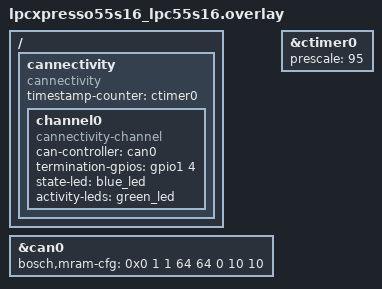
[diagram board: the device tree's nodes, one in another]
/*
 * Copyright (c) 2024 Henrik Brix Andersen <henrik@brixandersen.dk>
 *
 * SPDX-License-Identifier: Apache-2.0
 */

#include <zephyr/dt-bindings/gpio/gpio.h>
#include "../app.overlay"

/ {
	cannectivity: cannectivity {
		compatible = "cannectivity";
		timestamp-counter = <&ctimer0>;

		channel0 {
			compatible = "cannectivity-channel";
			can-controller = <&can0>;
			termination-gpios = <&gpio1 4 GPIO_ACTIVE_HIGH>; /* Red LED for testing */
			state-led = <&blue_led>;
			activity-leds = <&green_led>;
		};
	};
};

&can0 {
	bosch,mram-cfg = <0x0 1 1 64 64 0 10 10>;
};

&ctimer0 {
	prescale = <95>;
};
